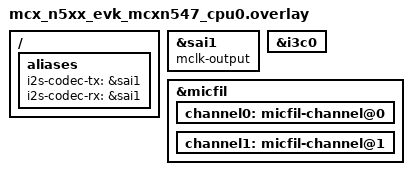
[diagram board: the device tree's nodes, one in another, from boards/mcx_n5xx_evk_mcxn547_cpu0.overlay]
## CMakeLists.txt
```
cmake_minimum_required(VERSION 3.20.0)
find_package(Zephyr REQUIRED HINTS $ENV{ZEPHYR_BASE})
project(audio_loopback)

file(GLOB app_sources src/*.c)
target_sources(app PRIVATE ${app_sources})
```

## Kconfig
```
# Copyright 2026 NXP
# SPDX-License-Identifier: Apache-2.0

source "Kconfig.zephyr"

choice SAMPLE_AUDIO_SOURCE
	prompt "Capture source the pipeline reads from"
	default SAMPLE_AUDIO_SOURCE_DMIC

config SAMPLE_AUDIO_SOURCE_DMIC
	bool "Digital microphone"

config SAMPLE_AUDIO_SOURCE_I2S
	bool "I2S receiver"

endchoice

config SAMPLE_AUDIO_GAIN_PERCENT
	int "Gain applied by the pipeline (percent)"
	default 90
	range 0 1000

config USE_I2S_TARGET_CODEC_CONTROLLER
	bool "I2S BCK is generated by a selected codec device"
	help
	  If selected, the I2S selected peripheral will be configured to consume
	  (receive) the I2S BCK and WS signals and the codec will be configured
	  to generate those. If not selected, the I2S peripheral will generate
	  them and the codec will be expected to consume them.
```

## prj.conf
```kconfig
CONFIG_LOG=y

CONFIG_MPIPE=y
CONFIG_MPIPE_BASE=y
CONFIG_MPIPE_BASE_CAPS_FILTER=y
CONFIG_MPIPE_AUD=y
CONFIG_MPIPE_PLAYER=y
CONFIG_ZBUS_MSG_SUBSCRIBER=y

CONFIG_AUDIO_DMIC=y
CONFIG_AUDIO_CODEC=y

CONFIG_I2S=y

CONFIG_SHELL=y
CONFIG_DEVICE_SHELL=y

CONFIG_MAIN_STACK_SIZE=4096

# The bus carries end-of-stream and errors, never data: it needs neither
# zbus priority boost nor zbus logging of its own.
CONFIG_ZBUS_PRIORITY_BOOST=n
CONFIG_ZBUS_LOG_LEVEL_ERR=y
```

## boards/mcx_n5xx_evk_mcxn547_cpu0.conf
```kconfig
# Copyright 2026 NXP
#
# SPDX-License-Identifier: Apache-2.0

CONFIG_I3C=y
CONFIG_AUDIO_CODEC=y

CONFIG_MPIPE_AUD_BUFFER_POOL_SZ_MAX=4096
CONFIG_MPIPE_AUD_BUFFER_POOL_NUM_MAX=8

CONFIG_DMA_TCD_QUEUE_SIZE=4
CONFIG_AUDIO_CODEC_DA7212=y
```

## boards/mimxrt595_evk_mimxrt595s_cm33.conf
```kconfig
#
# Copyright 2026 NXP
#
# SPDX-License-Identifier: Apache-2.0
#

CONFIG_I3C=y
CONFIG_AUDIO_CODEC=y

CONFIG_MPIPE_AUD_BUFFER_POOL_SZ_MAX=4096
CONFIG_MPIPE_AUD_BUFFER_POOL_NUM_MAX=8

CONFIG_USE_I2S_TARGET_CODEC_CONTROLLER=y

# The I2S codec sink primes AUD_I2S_SINK_START_PRIME (3) writes into the I2S TX
# queue before issuing I2S_TRIGGER_START. The TX in_queue must therefore be able
# to hold at least that many buffers, otherwise the priming writes block on a
# full queue, START never fires, and the shared buffer pool drains.
CONFIG_I2S_MCUX_FLEXCOMM_TX_BLOCK_COUNT=4
```

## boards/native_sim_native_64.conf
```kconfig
#
# Copyright 2026 NXP
#
# SPDX-License-Identifier: Apache-2.0
#

CONFIG_AUDIO_CODEC=y
CONFIG_AUDIO_CODEC_DUMMY=y
CONFIG_AUDIO_DMIC=y
CONFIG_AUDIO_DMIC_NATIVE_SIM=y
CONFIG_I2S=y
CONFIG_I2S_NATIVE_SIM=y

CONFIG_MPIPE_AUD_BUFFER_POOL_SZ_MAX=4096
CONFIG_MPIPE_AUD_BUFFER_POOL_NUM_MAX=9

CONFIG_I2S_NATIVE_SIM_TX_FILE_PATH="build/native_sim_audio_pipeline_tx.pcm"

# Bound the sim I2S queue: the pool must cover RX and TX concurrently.
CONFIG_I2S_NATIVE_SIM_QUEUE_SIZE=3
```

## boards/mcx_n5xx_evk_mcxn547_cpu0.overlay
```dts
/*
 * Copyright 2026 NXP
 *
 * SPDX-License-Identifier: Apache-2.0
 */

/ {
	aliases {
		i2s-codec-tx = &sai1;
		/* Only sai1 is pin-routed on this board; it carries both directions. */
		i2s-codec-rx = &sai1;
	};
};

&sai1 {
	mclk-output;
};

&i3c0 {
	status = "okay";
};

dmic_dev: &micfil {
	channel0: micfil-channel@0 {
		status = "okay";
	};

	channel1: micfil-channel@1 {
		status = "okay";
	};
};
```

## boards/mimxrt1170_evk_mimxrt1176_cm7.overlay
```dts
/*
 * Copyright 2026 NXP
 *
 * SPDX-License-Identifier: Apache-2.0
 */

/ {
	aliases {
		/* SAI1 carries both directions: the WM8962 is full duplex on it. */
		i2s-codec-rx = &sai1;
	};
};

&sai1 {
	mclk-output;
};

dmic_dev: &micfil {
	channel0: micfil-channel@0 {
		status = "okay";
	};

	channel1: micfil-channel@1 {
		status = "okay";
	};
};
```

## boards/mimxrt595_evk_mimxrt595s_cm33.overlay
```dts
/*
 * Copyright 2026 NXP
 *
 * SPDX-License-Identifier: Apache-2.0
 */

/ {
	aliases {
		i2s-codec-rx = &i2s0;
		i2s-codec-tx = &i2s1;
	};
};

&i3c0 {
	clk-divider = <20>;

	status = "okay";
};

&i2s0 {
	status = "okay";
};

&i2s1 {
	status = "okay";
};

dmic_dev: &dmic0 {
	status = "okay";
};
```

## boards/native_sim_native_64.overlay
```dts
/*
 * Copyright 2026 NXP
 *
 * SPDX-License-Identifier: Apache-2.0
 */

/ {
	aliases {
		i2s-codec-rx = &i2s_rx0;
		i2s-codec-tx = &i2s_tx0;
	};
};

dmic_dev: &dmic0 {
	status = "okay";
};

&i2s_rx0 {
	status = "okay";
};

&i2s_tx0 {
	status = "okay";
};

&audio_codec {
	status = "okay";
};
```

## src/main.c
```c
/*
 * Copyright 2025 NXP
 *
 * SPDX-License-Identifier: Apache-2.0
 */

#include <zephyr/kernel.h>
#include <zephyr/logging/log.h>

#include <zephyr/mpipe/mpipe.h>
#include <zephyr/mpipe/aud/mpipe_aud.h>
#include <zephyr/mpipe/aud/mpipe_aud_buffer_pool.h>
#include <zephyr/mpipe/aud/mpipe_aud_dmic_src.h>
#include <zephyr/mpipe/aud/mpipe_aud_gain.h>
#include <zephyr/mpipe/aud/mpipe_aud_i2s_codec_sink.h>
#include <zephyr/mpipe/aud/mpipe_aud_i2s_src.h>
#include <zephyr/mpipe/base/mpipe_caps_filter.h>
#include <zephyr/mpipe/utils/mpipe_player.h>

LOG_MODULE_REGISTER(main);

enum {
	PIPE_ID,
	AUD_SRC_ID,
	CAPS_FILTER_ID,
	AUD_GAIN_ID,
	I2S_SINK_ID,
};

__nocache struct k_mem_slab mem_slab;

static struct mpipe pipe;

/* Which side of the I2S link drives BCLK and WS, from the board configuration */
#ifdef CONFIG_USE_I2S_TARGET_CODEC_CONTROLLER
#define I2S_CLK_ROLE MPIPE_AUD_I2S_TARGET_CODEC_CONTROLLER
#else
#define I2S_CLK_ROLE MPIPE_AUD_I2S_CONTROLLER_CODEC_TARGET
#endif

#ifdef CONFIG_SAMPLE_AUDIO_SOURCE_I2S
static struct mpipe_aud_i2s_src source;
#define audio_src_init(src, id)                                                                    \
	mpipe_aud_i2s_src_init((src), (id), DEVICE_DT_GET(DT_ALIAS(i2s_codec_rx)))
#else
static struct mpipe_aud_dmic_src source;
#define audio_src_init(src, id) mpipe_aud_dmic_src_init((src), (id))
#endif
static struct mpipe_caps_filter caps_filter;
static struct mpipe_aud_gain gain;
static struct mpipe_aud_i2s_codec_sink sink;
static struct mpipe_player player;

int main(void)
{
	int gain_val = CONFIG_SAMPLE_AUDIO_GAIN_PERCENT;
	struct mpipe_structure caps;
	int ret;

	ret = mpipe_pipeline_init(&pipe, PIPE_ID);
	if (ret < 0) {
		goto err;
	}
	ret = audio_src_init(&source, AUD_SRC_ID);
	if (ret < 0) {
		goto err;
	}
	ret = mpipe_caps_filter_init(&caps_filter, CAPS_FILTER_ID);
	if (ret < 0) {
		goto err;
	}
	ret = mpipe_aud_gain_init(&gain, AUD_GAIN_ID);
	if (ret < 0) {
		goto err;
	}
	ret = mpipe_aud_i2s_codec_sink_init(&sink, I2S_SINK_ID);
	if (ret < 0) {
		goto err;
	}

	ret = mpipe_object_set_properties((struct mpipe_object *)&source,
					  MPIPE_PROP_AUD_SRC_SLAB_PTR, &mem_slab,
					  MPIPE_PROP_LIST_END);
	if (ret < 0) {
		goto err;
	}

#ifdef CONFIG_SAMPLE_AUDIO_SOURCE_I2S
	ret = mpipe_object_set_properties((struct mpipe_object *)&source,
					  MPIPE_PROP_AUD_I2S_SRC_CLK_ROLE,
					  (void *)(uintptr_t)I2S_CLK_ROLE,
					  MPIPE_PROP_LIST_END);
	if (ret < 0) {
		goto err;
	}
#endif
	ret = mpipe_object_set_properties((struct mpipe_object *)&sink,
					  MPIPE_PROP_AUD_SINK_SLAB_PTR, &mem_slab,
					  MPIPE_PROP_AUD_SINK_CLK_ROLE,
					  (void *)(uintptr_t)I2S_CLK_ROLE,
					  MPIPE_PROP_LIST_END);
	if (ret < 0) {
		goto err;
	}
	ret = mpipe_object_set_properties((struct mpipe_object *)&gain,
					  MPIPE_PROP_AUD_TRANSFORM_GAIN, &gain_val,
					  MPIPE_PROP_LIST_END);
	if (ret < 0) {
		goto err;
	}

	ret = mpipe_structure_init_fields(&caps, MPIPE_MEDIA_AUDIO_PCM,
					  MPIPE_CAPS_FRAME_INTERVAL, MPIPE_TYPE_UINT, 10000,
					  MPIPE_CAPS_NUM_CHANNELS, MPIPE_TYPE_UINT, 2,
					  MPIPE_CAPS_END);
	if (ret < 0) {
		goto err;
	}
	ret = mpipe_object_set_properties((struct mpipe_object *)&caps_filter,
					  MPIPE_PROP_BASE_CAPS_FILTER_CAPS, &caps,
					  MPIPE_PROP_LIST_END);
	if (ret < 0) {
		goto err;
	}

	ret = mpipe_bin_add((struct mpipe_bin *)&pipe, (struct mpipe_element *)&source,
			    (struct mpipe_element *)&caps_filter, (struct mpipe_element *)&gain,
			    (struct mpipe_element *)&sink, NULL);
	if (ret < 0) {
		goto err;
	}
	ret = mpipe_element_link((struct mpipe_element *)&source,
				 (struct mpipe_element *)&caps_filter,
				 (struct mpipe_element *)&gain,
				 (struct mpipe_element *)&sink, NULL);
	if (ret < 0) {
		goto err;
	}

	ret = mpipe_player_init(&player, &pipe);
	if (ret < 0) {
		goto err;
	}

	LOG_INF("player ready -- controls: player play | pause | stop | replay | status");
	mpipe_player_play(&player);

	return 0;

err:
	LOG_ERR("Aborting sample (%d)", ret);
	return ret != 0 ? ret : -EIO;
}
```
